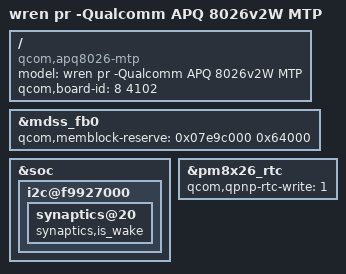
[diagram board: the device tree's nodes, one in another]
/* Copyright (c) 2015, The Linux Foundation. All rights reserved.
 *
 * This program is free software; you can redistribute it and/or modify
 * it under the terms of the GNU General Public License version 2 and
 * only version 2 as published by the Free Software Foundation.
 *
 * This program is distributed in the hope that it will be useful,
 * but WITHOUT ANY WARRANTY; without even the implied warranty of
 * MERCHANTABILITY or FITNESS FOR A PARTICULAR PURPOSE.  See the
 * GNU General Public License for more details.
 */


/dts-v1/;
/*+++ASUS_BSP: rename #include "apq8026-v2.dtsi"*/
#include "wren_pr_105_apq8026-v2.dtsi"
#include "msm8226-w-memory.dtsi"
#include "msm8226-w-qseecom.dtsi"
#include "msm8226-w-sharedmem.dtsi"
/*+++ASUS_BSP: rename #include "msm8226-720p-mtp.dtsi"*/
#include "wren_pr_msm8226-720p-mtp.dtsi"
#include "msm8x26w-gpu.dtsi"

/ {
	model = "wren pr -Qualcomm APQ 8026v2W MTP";
	compatible = "qcom,apq8026-mtp", "qcom,apq8026", "qcom,mtp";
	qcom,board-id = <8 4102>; /*chage from 4 to 4002 for WI300QF(300)+WREN_PR(1)*/
};

&mdss_fb0 {
	/* cont_splash memory*/
	qcom,memblock-reserve = <0x07e9c000 0x64000>;
};


&soc {
	i2c@f9927000 {
		synaptics@20 {
			/delete-property/ synaptics,power-down;
			/delete-property/ synaptics,disable-gpios;
			synaptics,is_wake;
		};
	};
};

&pm8x26_rtc {
	qcom,qpnp-rtc-write = <1>;
};
